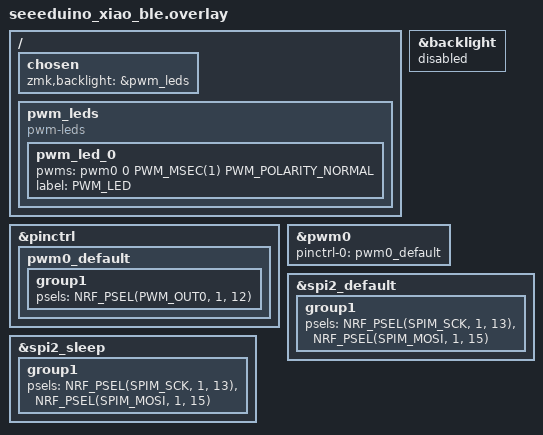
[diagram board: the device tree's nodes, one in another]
#include <dt-bindings/pwm/pwm.h>

&backlight { status = "disabled"; };


/ {
	chosen {
        zmk,backlight = &pwm_leds;
    };
	
    pwm_leds: pwm_leds {
        compatible = "pwm-leds";
        pwm_led_0 {
			status = "okay";
            pwms = <&pwm0 0 PWM_MSEC(1) PWM_POLARITY_NORMAL>;
			label = "PWM_LED";
        };
    };
};


&pinctrl {
    // Other pinctrl definitions for other hardware
    pwm0_default: pwm0_default {
        group1 {
            psels = <NRF_PSEL(PWM_OUT0, 1, 12)>;
        };
    };
};

&pwm0 {
    status = "okay";
    pinctrl-0 = <&pwm0_default>;
    pinctrl-names = "default";
};



&spi2_default {
	group1 {
		psels = <NRF_PSEL(SPIM_SCK, 1, 13)>,
			<NRF_PSEL(SPIM_MOSI, 1, 15)>;
	};
};

&spi2_sleep {
	group1 {
		psels = <NRF_PSEL(SPIM_SCK, 1, 13)>,
			<NRF_PSEL(SPIM_MOSI, 1, 15)>;
	};
};
